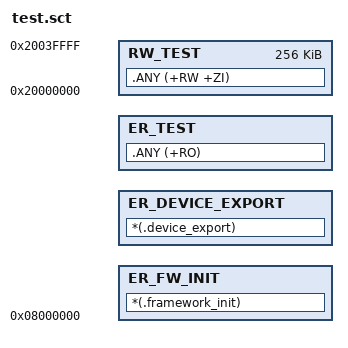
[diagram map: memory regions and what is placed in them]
LR_TEST 0x08000000 0x00100000
{
 ER_FW_INIT 0x08000000 { *(.framework_init) }
 ER_DEVICE_EXPORT +0 { *(.device_export) }
 ER_TEST +0 { .ANY (+RO) }
 RW_TEST 0x20000000 0x00040000 { .ANY (+RW +ZI) }
}
